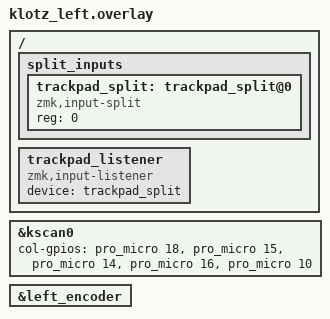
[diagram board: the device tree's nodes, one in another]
/*
 * Copyright (c) 2022 GEIST
 *
 * SPDX-License-Identifier: MIT
 */

#include "klotz.dtsi"

&kscan0 {
	col-gpios
		= <&pro_micro 18 GPIO_ACTIVE_HIGH>
		, <&pro_micro 15 GPIO_ACTIVE_HIGH>
		, <&pro_micro 14 GPIO_ACTIVE_HIGH>
		, <&pro_micro 16 GPIO_ACTIVE_HIGH>
		, <&pro_micro 10 GPIO_ACTIVE_HIGH>
		;
};

&left_encoder {
	status = "okay";
};

/*
 * Central (left) side of the trackpad split: receive the peripheral's pointing
 * events and feed them to an input-listener (turns them into HID mouse reports).
 */
/ {
	split_inputs {
		#address-cells = <1>;
		#size-cells = <0>;

		trackpad_split: trackpad_split@0 {
			compatible = "zmk,input-split";
			reg = <0>;
		};
	};

	trackpad_listener {
		compatible = "zmk,input-listener";
		device = <&trackpad_split>;
	};
};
